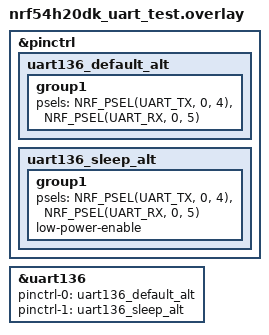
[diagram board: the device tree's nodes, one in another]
/*
 * Copyright (c) 2023 Nordic Semiconductor ASA
 *
 * SPDX-License-Identifier: LicenseRef-Nordic-5-Clause
 */

#include "../boards/nrf54h20dk_nrf54h20_cpurad_soc1.overlay"

&pinctrl {
	uart136_default_alt: uart136_default_alt {
		group1 {
			psels = <NRF_PSEL(UART_TX, 0, 4)>,
				<NRF_PSEL(UART_RX, 0, 5)>;
		};
	};

	uart136_sleep_alt: uart136_sleep_alt {
		group1 {
			psels = <NRF_PSEL(UART_TX, 0, 4)>,
				<NRF_PSEL(UART_RX, 0, 5)>;
			low-power-enable;
		};
	};
};

&uart136 {
	pinctrl-0 = <&uart136_default_alt>;
	pinctrl-1 = <&uart136_sleep_alt>;
};
